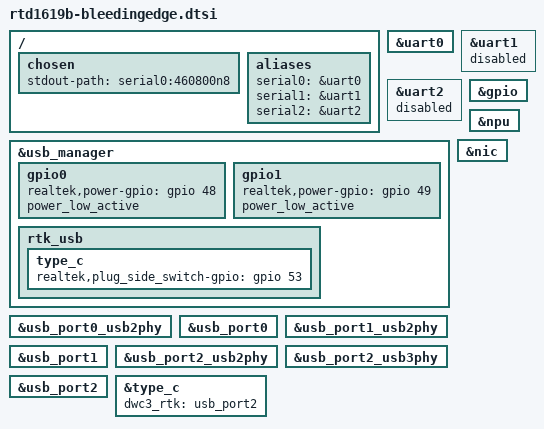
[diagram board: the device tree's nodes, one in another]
// SPDX-License-Identifier: (GPL-2.0-or-later OR BSD-2-Clause)
/*
 * Copyright (c) 2020 Realtek Semiconductor Corp.
 */
/dts-v1/;
#include "rtd16xxb.dtsi"
/ {
	chosen {
		stdout-path = "serial0:460800n8";
	};
	aliases {
		serial0 = &uart0;
		serial1 = &uart1;
		serial2 = &uart2;
	};
};
/* debug console (J1) */
&uart0 {
	status = "okay";
};
/* M.2 slot (CON2) */
&uart1 {
	status = "disabled";
};
&uart2 {
	status = "disabled";
};

&gpio {
	status = "okay";
};

&usb_manager {
	status = "okay";

	gpio0 {
		realtek,power-gpio = <&gpio 48 GPIO_ACTIVE_HIGH>;
		power_low_active;
	};

	gpio1 {
		realtek,power-gpio = <&gpio 49 GPIO_ACTIVE_HIGH>;
		power_low_active;
	};

	rtk_usb {
		type_c {
			realtek,plug_side_switch-gpio = <&gpio 53 GPIO_ACTIVE_HIGH>;
		};
	};
};

&usb_port0_usb2phy {
	status = "okay";
};

&usb_port0 {
	status = "okay";
};

&usb_port1_usb2phy {
	status = "okay";
};

&usb_port1 {
	status = "okay";
};

&usb_port2_usb2phy {
	status = "okay";
};

&usb_port2_usb3phy {
	status = "okay";
};

&usb_port2 {
	status = "okay";
};

&type_c {
	status = "okay";

	dwc3_rtk = <&usb_port2>;
};

&npu {
	status = "okay";
};

&nic {
	status = "okay";
};
